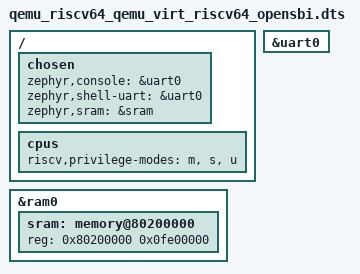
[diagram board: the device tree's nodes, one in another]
/* Copyright (c) 2026 Alexios Lyrakis */
/* SPDX-License-Identifier: Apache-2.0 */

/dts-v1/;

#include <qemu/virt-riscv64.dtsi>
#include <qemu/virt-riscv-plic.dtsi>

/ {
	chosen {
		zephyr,console = &uart0;
		zephyr,shell-uart = &uart0;
		zephyr,sram = &sram;
	};

	cpus {
		riscv,privilege-modes = "m", "s", "u";
	};
};

/*
 * When launched as an S-mode payload under an external SBI (OpenSBI), the
 * M-mode firmware occupies the bottom of RAM (0x80000000 onwards). Move the
 * Zephyr image up by 2 MiB so it does not overlap OpenSBI, and shrink the
 * region by the same amount so it still ends at the top of the 256 MiB the
 * QEMU virt machine provides (0x90000000).
 */
&ram0 {
	#address-cells = <1>;
	#size-cells = <1>;

	sram: memory@80200000 {
		device_type = "memory";
		reg = <0x80200000 0x0fe00000>;
	};
};

&uart0 {
	status = "okay";
};
